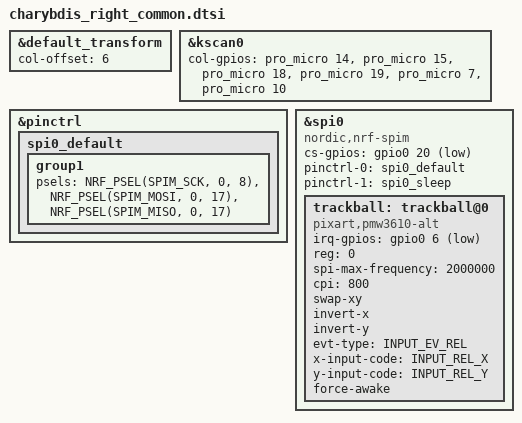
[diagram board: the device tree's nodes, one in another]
/*
 * Copyright (c) 2024 The ZMK Contributors
 * SPDX-License-Identifier: MIT
 *
 * Common hardware configuration for Charybdis right keyboard variants
 * Shared between charybdis_right_standalone and dongle_charybdis_right
 */

#include "charybdis.dtsi"
#include <zephyr/dt-bindings/input/input-event-codes.h>

&default_transform {
	col-offset = <6>;
};

&kscan0 {
    col-gpios
        /* 오른쪽은 왼쪽이랑 반대로 다시 뒤집는다 */
        = <&pro_micro 14 (GPIO_ACTIVE_HIGH | GPIO_PULL_DOWN)> /* Col 6 */
        , <&pro_micro 15 (GPIO_ACTIVE_HIGH | GPIO_PULL_DOWN)> /* Col 7 */
        , <&pro_micro 18 (GPIO_ACTIVE_HIGH | GPIO_PULL_DOWN)> /* Col 8 */
        , <&pro_micro 19 (GPIO_ACTIVE_HIGH | GPIO_PULL_DOWN)> /* Col 9 */
        , <&pro_micro  7 (GPIO_ACTIVE_HIGH | GPIO_PULL_DOWN)> /* Col 10 */
        , <&pro_micro 10 (GPIO_ACTIVE_HIGH | GPIO_PULL_DOWN)> /* Col 11 */
    ;
};

&pinctrl {
    spi0_default: spi0_default {
        group1 {
            /* 트랙볼 핀은 원래 하드웨어 자리(8, 17)로 원복 */
            psels = <NRF_PSEL(SPIM_SCK, 0, 8)>, 
                    <NRF_PSEL(SPIM_MOSI, 0, 17)>,
                    <NRF_PSEL(SPIM_MISO, 0, 17)>;
        };
    };
};

&spi0 {
    /* CS랑 IRQ도 원래 쓰던 핀(20, 6)으로 원복 */
    cs-gpios = <&gpio0 20 GPIO_ACTIVE_LOW>; 
    trackball: trackball@0 {
        irq-gpios = <&gpio0 6 (GPIO_ACTIVE_LOW | GPIO_PULL_UP)>; 
    };
};

&spi0 {
    status = "okay";
    compatible = "nordic,nrf-spim";
    pinctrl-0 = <&spi0_default>;
    pinctrl-1 = <&spi0_sleep>;
    pinctrl-names = "default", "sleep";
    cs-gpios = <&gpio0 20 GPIO_ACTIVE_LOW>;

    trackball: trackball@0 {
        status = "okay";
        compatible = "pixart,pmw3610-alt";
        reg = <0>;
        spi-max-frequency = <2000000>;
        irq-gpios = <&gpio0 6 (GPIO_ACTIVE_LOW | GPIO_PULL_UP)>;
        cpi = <800>;
        swap-xy;
        invert-x;
        invert-y;
        evt-type = <INPUT_EV_REL>;
        x-input-code = <INPUT_REL_X>;
        y-input-code = <INPUT_REL_Y>;
        force-awake;
        /* keep the sensor awake while ZMK activity state is ACTIVE,
           fallback to normal downshift mode after ZMK goes into IDLE / SLEEP mode.
           thus, the sensor would be a `wakeup-source` */
        // force-awake-4ms-mode;
        /* while force-awake is acitvated, enable this mode to force sampling per
           4ms, where the default sampling rate is 8ms. */
        /* NOTE: apply this mode if you need 250Hz with direct USB connection. */
    };
};

